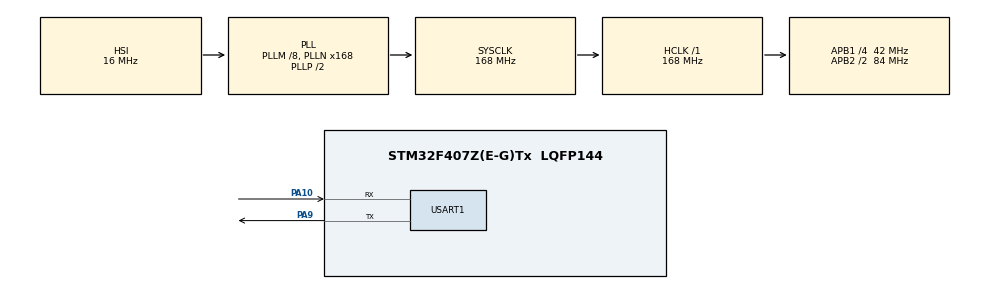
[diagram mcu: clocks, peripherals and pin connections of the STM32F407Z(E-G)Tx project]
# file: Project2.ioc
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FREERTOS.Tasks01=defaultTask,0,128,StartDefaultTask,Default,NULL,Dynamic,NULL,NULL;myTask02,-3,128,StartTask02,Default,NULL,Dynamic,NULL,NULL
FREERTOS.configUSE_PREEMPTION=1
Mcu.Family=STM32F4
Mcu.Name=STM32F407Z(E-G)Tx
Mcu.Package=LQFP144
NVIC.PriorityGroup=NVIC_PRIORITYGROUP_4
NVIC.TIM2_IRQn=true\:15\:0\:false\:false\:true\:false\:false\:true\:true
NVIC.TimeBase=TIM2_IRQn
NVIC.TimeBaseIP=TIM2
NVIC.USART1_IRQn=true\:5\:0\:false\:false\:true\:true\:true\:true\:true
PA10.Mode=Asynchronous
PA10.Signal=USART1_RX
PA13.Mode=Serial_Wire
PA13.Signal=SYS_JTMS-SWDIO
PA14.Mode=Serial_Wire
PA14.Signal=SYS_JTCK-SWCLK
PA9.Mode=Asynchronous
PA9.Signal=USART1_TX
PC14-OSC32_IN.Mode=LSE-External-Oscillator
PC14-OSC32_IN.Signal=RCC_OSC32_IN
PC15-OSC32_OUT.Mode=LSE-External-Oscillator
PC15-OSC32_OUT.Signal=RCC_OSC32_OUT
PH0-OSC_IN.Mode=HSE-External-Oscillator
PH0-OSC_IN.Signal=RCC_OSC_IN
PH1-OSC_OUT.Mode=HSE-External-Oscillator
PH1-OSC_OUT.Signal=RCC_OSC_OUT
ProjectManager.HeapSize=0x200
ProjectManager.StackSize=0x400
ProjectManager.TargetToolchain=STM32CubeIDE
RCC.48MHZClocksFreq_Value=84000000
RCC.AHBFreq_Value=168000000
RCC.APB1CLKDivider=RCC_HCLK_DIV4
RCC.APB1Freq_Value=42000000
RCC.APB1TimFreq_Value=84000000
RCC.APB2CLKDivider=RCC_HCLK_DIV2
RCC.APB2Freq_Value=84000000
RCC.APB2TimFreq_Value=168000000
RCC.CortexFreq_Value=168000000
RCC.HCLKFreq_Value=168000000
RCC.HSE_VALUE=8000000
RCC.HSI_VALUE=16000000
RCC.PLLM=8
RCC.PLLN=168
RCC.SYSCLKFreq_VALUE=168000000
RCC.SYSCLKSource=RCC_SYSCLKSOURCE_PLLCLK
RCC.VCOOutputFreq_Value=336000000
USART1.VirtualMode=VM_ASYNC
VP_FREERTOS_VS_CMSIS_V1.Mode=CMSIS_V1
VP_SYS_VS_tim2.Mode=TIM2
board=custom

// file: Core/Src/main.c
/* USER CODE BEGIN Header */
/**
  ******************************************************************************
  * @file           : main.c
  * @brief          : Main program body
  ******************************************************************************
  * @attention
  *
  * Copyright (c) 2024 STMicroelectronics.
  * All rights reserved.
  *
  * This software is licensed under terms that can be found in the LICENSE file
  * in the root directory of this software component.
  * If no LICENSE file comes with this software, it is provided AS-IS.
  *
  ******************************************************************************
  */
/* USER CODE END Header */
#include "main.h"
#include "cmsis_os.h"

/* USER CODE BEGIN Includes */
#include "stdio.h"
#include "string.h"
/* USER CODE END Includes */

UART_HandleTypeDef huart1;

osThreadId defaultTaskHandle;
osThreadId myTask02Handle;
/* USER CODE BEGIN PV */
osThreadId AboveNormalHandle;
/* USER CODE END PV */

void SystemClock_Config(void);
static void MX_GPIO_Init(void);
static void MX_USART1_UART_Init(void);
void StartDefaultTask(void const * argument);
void StartTask02(void const * argument);

/* USER CODE BEGIN PFP */
void AboveNormalTask(void const * parameter); //Named for a task
/* USER CODE END PFP */

/* USER CODE BEGIN 0 */
//print status qua uart
#ifdef __GNUC__
#define PUTCHAR_PROTOTYPE int __io_putchar(int ch)
#else
#define PUTCHAR_PROTOTYPE int fputc(int ch, FILE *f)
#endif /* __GNUC__ */

PUTCHAR_PROTOTYPE
{
	HAL_UART_Transmit(&huart1, (uint8_t *)&ch, 1, HAL_MAX_DELAY);
	return ch;
}

//void stm32_log(char *s){
//	HAL_UART_Transmit(&huart1, (uint8_t *)s, strlen(s), 10);
//}
/* USER CODE END 0 */

int main(void)
{

  /* MCU Configuration--------------------------------------------------------*/

  /* Reset of all peripherals, Initializes the Flash interface and the Systick. */
  HAL_Init();

  /* Configure the system clock */
  SystemClock_Config();

  /* Initialize all configured peripherals */
  MX_GPIO_Init();
  MX_USART1_UART_Init();

  /* Create the thread(s) */
  /* definition and creation of defaultTask */
  osThreadDef(defaultTask, StartDefaultTask, osPriorityNormal, 0, 128);
  defaultTaskHandle = osThreadCreate(osThread(defaultTask), NULL);

  /* definition and creation of myTask02 */
  osThreadDef(myTask02, StartTask02, osPriorityIdle, 0, 128);
  myTask02Handle = osThreadCreate(osThread(myTask02), NULL);

  /* USER CODE BEGIN RTOS_THREADS */
  osThreadDef(Task1, AboveNormalTask, osPriorityAboveNormal, 0, 128);// the number 0 is has one task
  AboveNormalHandle = osThreadCreate(osThread(Task1), NULL); // transmit the name of task, null is no parameter is transmitted
  /* add threads, ... */
  /* USER CODE END RTOS_THREADS */

  /* Start scheduler */
  osKernelStart();

  /* We should never get here as control is now taken by the scheduler */
  /* Infinite loop */
  while (1)
  {

  }
}

void SystemClock_Config(void)
{
  RCC_OscInitTypeDef RCC_OscInitStruct = {0};
  RCC_ClkInitTypeDef RCC_ClkInitStruct = {0};

  /** Configure the main internal regulator output voltage
  */
  __HAL_RCC_PWR_CLK_ENABLE();
  __HAL_PWR_VOLTAGESCALING_CONFIG(PWR_REGULATOR_VOLTAGE_SCALE1);

  /** Initializes the RCC Oscillators according to the specified parameters
  * in the RCC_OscInitTypeDef structure.
  */
  RCC_OscInitStruct.OscillatorType = RCC_OSCILLATORTYPE_HSI;
  RCC_OscInitStruct.HSIState = RCC_HSI_ON;
  RCC_OscInitStruct.HSICalibrationValue = RCC_HSICALIBRATION_DEFAULT;
  RCC_OscInitStruct.PLL.PLLState = RCC_PLL_ON;
  RCC_OscInitStruct.PLL.PLLSource = RCC_PLLSOURCE_HSI;
  RCC_OscInitStruct.PLL.PLLM = 8;
  RCC_OscInitStruct.PLL.PLLN = 168;
  RCC_OscInitStruct.PLL.PLLP = RCC_PLLP_DIV2;
  RCC_OscInitStruct.PLL.PLLQ = 4;
  if (HAL_RCC_OscConfig(&RCC_OscInitStruct) != HAL_OK)
  {
    Error_Handler();
  }

  /** Initializes the CPU, AHB and APB buses clocks
  */
  RCC_ClkInitStruct.ClockType = RCC_CLOCKTYPE_HCLK|RCC_CLOCKTYPE_SYSCLK
                              |RCC_CLOCKTYPE_PCLK1|RCC_CLOCKTYPE_PCLK2;
  RCC_ClkInitStruct.SYSCLKSource = RCC_SYSCLKSOURCE_PLLCLK;
  RCC_ClkInitStruct.AHBCLKDivider = RCC_SYSCLK_DIV1;
  RCC_ClkInitStruct.APB1CLKDivider = RCC_HCLK_DIV4;
  RCC_ClkInitStruct.APB2CLKDivider = RCC_HCLK_DIV2;

  if (HAL_RCC_ClockConfig(&RCC_ClkInitStruct, FLASH_LATENCY_5) != HAL_OK)
  {
    Error_Handler();
  }
}

static void MX_USART1_UART_Init(void)
{

  huart1.Instance = USART1;
  huart1.Init.BaudRate = 115200;
  huart1.Init.WordLength = UART_WORDLENGTH_8B;
  huart1.Init.StopBits = UART_STOPBITS_1;
  huart1.Init.Parity = UART_PARITY_NONE;
  huart1.Init.Mode = UART_MODE_TX_RX;
  huart1.Init.HwFlowCtl = UART_HWCONTROL_NONE;
  huart1.Init.OverSampling = UART_OVERSAMPLING_16;
  if (HAL_UART_Init(&huart1) != HAL_OK)
  {
    Error_Handler();
  }

}

static void MX_GPIO_Init(void)
{

  /* GPIO Ports Clock Enable */
  __HAL_RCC_GPIOC_CLK_ENABLE();
  __HAL_RCC_GPIOH_CLK_ENABLE();
  __HAL_RCC_GPIOA_CLK_ENABLE();

}

/* USER CODE BEGIN 4 */
void AboveNormalTask(void const * parameter){
	uint8_t j = 0;
	while(1){
		printf("Hello from Task1 %d\n", j);
		j++;
		osDelay(1000);
		if(j == 5){
			osThreadSuspend(NULL);
		}
		if(j == 6){
			osThreadTerminate(defaultTaskHandle);
		}
	}
}

/* USER CODE END 4 */

void StartDefaultTask(void const * argument)
{
  /* USER CODE BEGIN 5 */
  /* Infinite loop */
  for(int i = 0; i < 20; i++)
  {
	  printf("Hello from Task0 %d\n", i);
	  osDelay(500);
	  if(i == 16){
		  osThreadResume(AboveNormalHandle);
	  }
  }
  /* USER CODE END 5 */
}

void StartTask02(void const * argument)
{
  for(;;){
  }
}

void HAL_TIM_PeriodElapsedCallback(TIM_HandleTypeDef *htim)
{
  if (htim->Instance == TIM2) {
    HAL_IncTick();
  }
}

void Error_Handler(void)
{
  __disable_irq();
  while (1)
  {
  }
}
